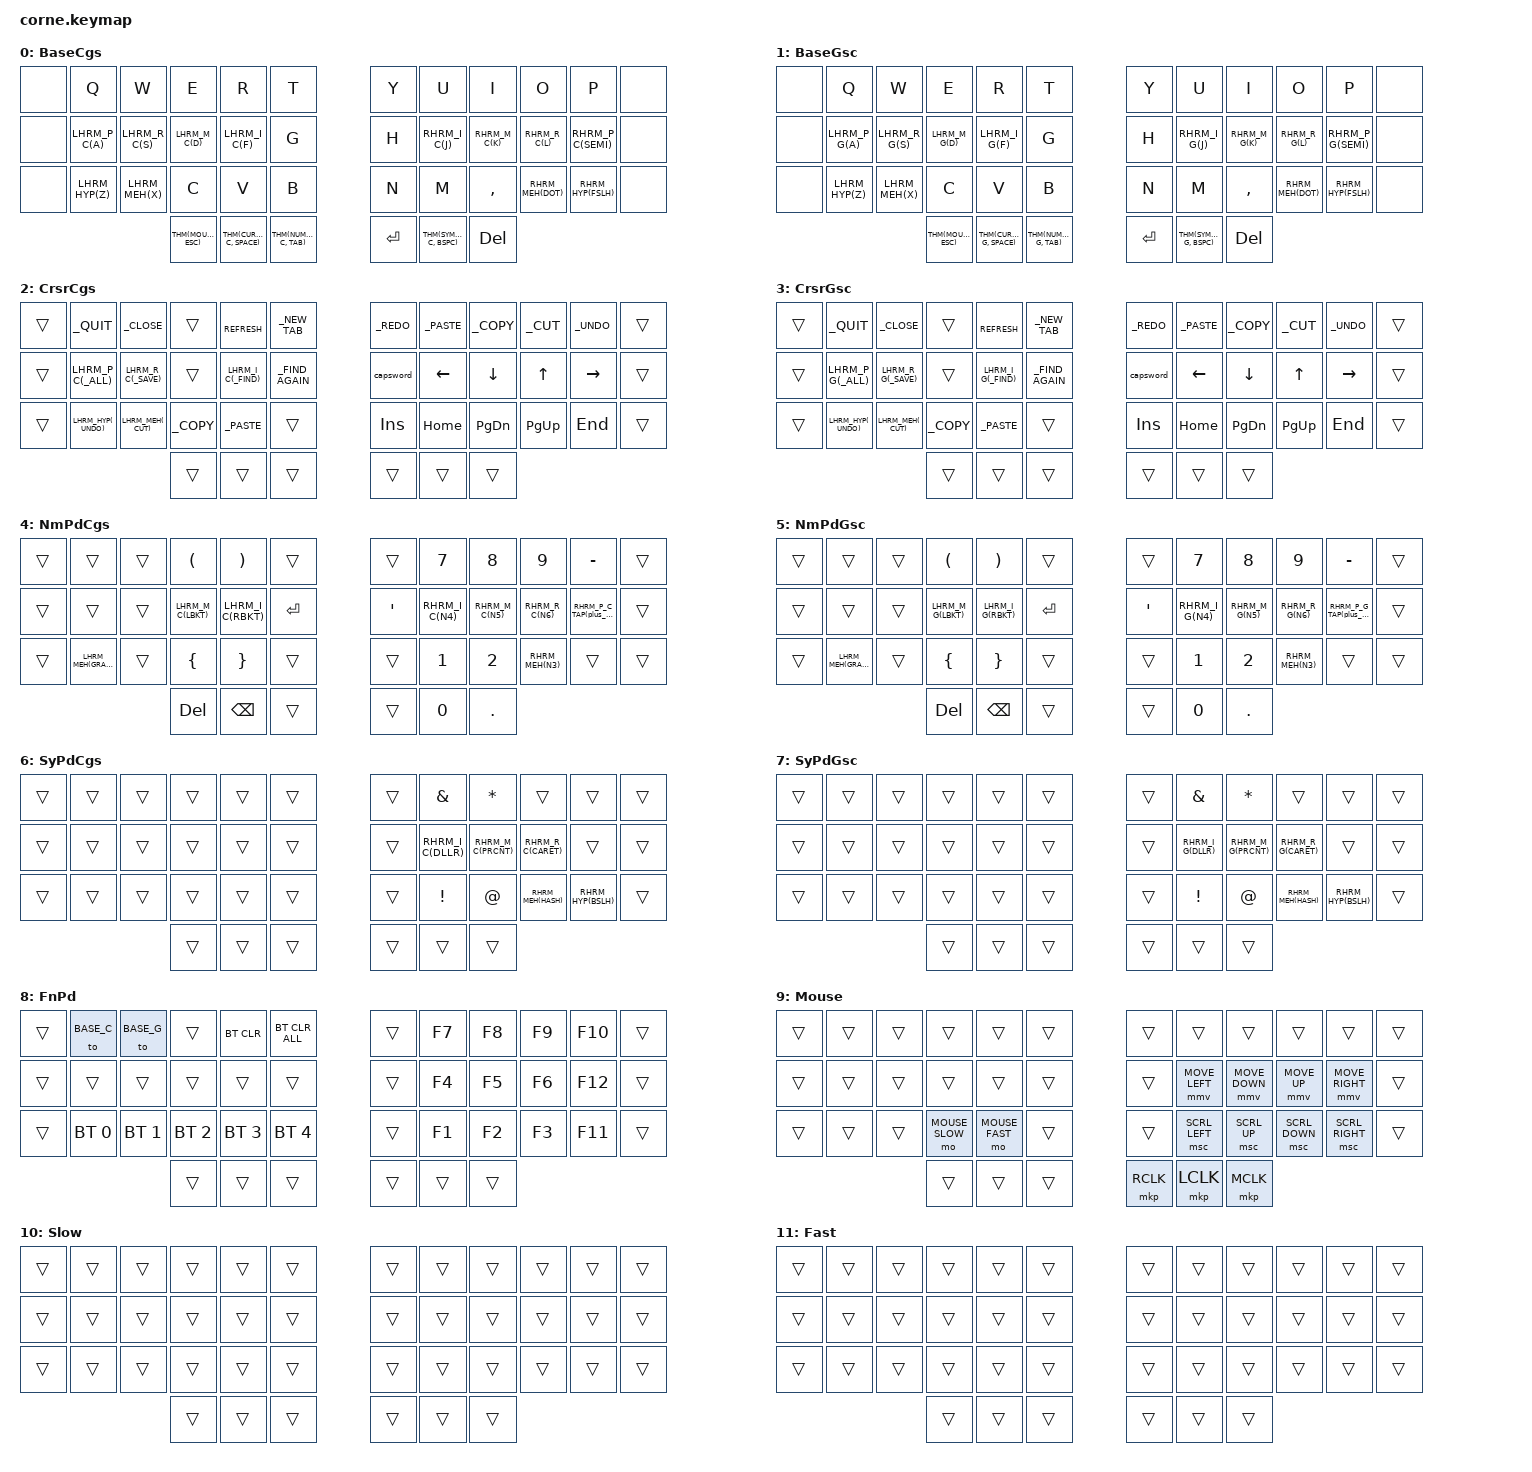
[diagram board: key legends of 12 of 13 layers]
#include <behaviors.dtsi>
#include <dt-bindings/zmk/bt.h>
#include <dt-bindings/zmk/keys.h>
#include <dt-bindings/zmk/pointing.h>
#include <input/processors.dtsi>
#include <zephyr/dt-bindings/input/input-event-codes.h>

// layer indexes
// need almost duplicate layers that override taps on the home row keys

// _C suffix stands for CAGS
#define BASE_C 0
#define CURSOR_C 2
#define NUM_PAD_C 4
#define SYM_PAD_C 6

// _G suffix stands for GASC
#define BASE_G 1
#define CURSOR_G 3
#define NUM_PAD_G 5
#define SYM_PAD_G 7

// layers that do not override taps on the home row keys
#define FCN_PAD 8
#define MOUSE 9
#define MOUSE_SLOW 10   // key 27 on MOUSE layer (hold 36 + 27)
#define MOUSE_FAST 11        // key 28 on MOUSE layer (hold 36 + 28)
#define FUNCTION 12

// #define NAV 7
// #define SYM 8
// #define EXTRA 9

/*
| Left Half:                  |  | Right Half:                 |
| 00 | 01 | 02 | 03 | 04 | 05 |  | 06 | 07 | 08 | 09 | 10 | 11 |
| 12 | 13 | 14 | 15 | 16 | 17 |  | 18 | 19 | 20 | 21 | 22 | 23 |
| 24 | 25 | 26 | 27 | 28 | 29 |  | 30 | 31 | 32 | 33 | 34 | 35 |
|              | 36 | 37 | 38 |  | 39 | 40 | 41 |              |
*/

#define RIGHT_KEY_POSITIONS 6 7 8 9 10 11 18 19 20 21 22 23 30 31 32 33 34 35 39 40 41
#define LEFT_KEY_POSITIONS 0 1 2 3 4 5 12 13 14 15 16 17 24 25 26 27 28 29 36 37 38
// Key positions for combos
#define LGUI_KEY_POSITION_C 15
#define LTHM_KEY_POSITION 37
#define A_KEY_POSITION 13
#define S_KEY_POSITION 14
#define F_KEY_POSITION 16
#define G_KEY_POSITION 17
#define Z_KEY_POSITION 25
#define X_KEY_POSITION 26
#define C_KEY_POSITION 27
#define V_KEY_POSITION 28
/* left-thumb-middle + left rolls (subset of LEFT_KEY_POSITIONS) */
#define LTHM_ROLL_KEY_POSITIONS A_KEY_POSITION S_KEY_POSITION F_KEY_POSITION G_KEY_POSITION Z_KEY_POSITION X_KEY_POSITION C_KEY_POSITION V_KEY_POSITION
#define RT_RET_KEY_POSITION 39
#define GRAVE_KEY_POSITION 13
#define GRAVE_COMBO_KEY_POSITION 25

// support left hand only operation
// these are all the same as the default combos but with the left hand cursor layer key
// add leading _ to prevent conflicts with ZMK
#define _CUT LG(X)
#define _COPY LG(C)
#define _PASTE LG(V)
#define _UNDO LG(Z)
#define _REDO LS(LG(Z))

#define _QUIT LG(Q)
#define _CLOSE LG(W)
#define _REFRESH LG(R)
// left only: copy url, new tab and paste
#define _NEW_TAB LG(T)
#define _ALL LG(A)
#define _SAVE LG(S)
#define _FIND LG(F)
#define _FIND_AGAIN LG(G)
// #define _DELETE LG(D) this is duplicate not delete

#define LHYPER LC(LA(LG(LSHFT)))
#define LMEH LC(LA(LSHFT))
#define RHYPER RC(RA(RG(RSHFT)))
#define RMEH RC(RA(RSHFT))

// CAGS home rom mods (macOS)
#define LHRM_P_C(tap) &hrm_l_p LCTRL tap
#define LHRM_R_C(tap) &hrm_l_r LALT tap
#define LHRM_M_C(tap) &hrm_l_m LGUI tap
#define LHRM_I_C(tap) &hrm_l_i LSHFT tap
#define RHRM_I_C(tap) &hrm_r_i RSHFT tap
#define RHRM_M_C(tap) &hrm_r_m RGUI tap
#define RHRM_R_C(tap) &hrm_r_r RALT tap
#define RHRM_P_C(tap) &hrm_r_p RCTRL tap
// Custom tap (mod-morph, etc.): needs hrm_r_p_<name> with bindings = <&kp>, <&name>
#define RHRM_P_C_TAP(name) &hrm_r_p_##name RCTRL 0

// GASC home row mods (Linux/Windows)
#define LHRM_P_G(tap) &hrm_l_p LGUI tap
#define LHRM_R_G(tap) &hrm_l_r LALT tap
#define LHRM_M_G(tap) &hrm_l_m LCTRL tap
#define LHRM_I_G(tap) &hrm_l_i LSHFT tap
#define RHRM_I_G(tap) &hrm_r_i RSHFT tap
#define RHRM_M_G(tap) &hrm_r_m RCTRL tap
#define RHRM_R_G(tap) &hrm_r_r RALT tap
#define RHRM_P_G(tap) &hrm_r_p RGUI tap
// Custom tap (mod-morph, etc.): needs hrm_r_p_<name> with bindings = <&kp>, <&name>
#define RHRM_P_G_TAP(name) &hrm_r_p_##name RGUI 0

// Hyper and Meh home row mods (OS-independent)
#define LHRM_HYP(tap) &hrm_l_p LHYPER tap
#define LHRM_MEH(tap) &hrm_l_r LMEH tap
#define RHRM_MEH(tap) &hrm_r_r RMEH tap
#define RHRM_HYP(tap) &hrm_r_p RHYPER tap

// Thumb row layer-tap
#define THM(layer, tap) &thumb_ht layer tap

/*
home row timings
For advanced tuning of HRM values, see: ZMK HRM Best Practice Values [SUNAKU]
[rovrevik: ZMK HRM Best Practice Values](https://docs.google.com/spreadsheets/d/1GeZ9UrOPWeVbzzsioyp9oQYQoQKxpyiTL4z8DZa1vXg)
[TaylorKey: ZMK HRM Best Practice Values](https://docs.google.com/spreadsheets/d/1ESgObQelyz4lnKlfwLYsmofLJulOMK5RdGBsopLe2o8)
started at "normal" and moving towards "faster".
*/
#define HRM_I_TAPPING_TERM_MS       282
#define HRM_I_QUICK_TAP_MS          374
#define HRM_I_REQUIRE_PRIOR_IDLE_MS 208

#define HRM_M_TAPPING_TERM_MS       299
#define HRM_M_QUICK_TAP_MS          374
#define HRM_M_REQUIRE_PRIOR_IDLE_MS 249

#define HRM_R_TAPPING_TERM_MS       324
#define HRM_R_QUICK_TAP_MS          374
#define HRM_R_REQUIRE_PRIOR_IDLE_MS 249

#define HRM_P_TAPPING_TERM_MS       357
#define HRM_P_QUICK_TAP_MS          374
#define HRM_P_REQUIRE_PRIOR_IDLE_MS 249

// thumb row layer timings
#define THUMB_TAPPING_TERM_MS       291
#define THUMB_QUICK_TAP_MS          374

/*
combo timeout
timeout default 50ms
zmk/app/dts/bindings/zmk,combos.yaml
*/
#define COMBO_TIMEOUT_MS                    125
#define LEFT_GUI_ROLL_COMBO_TIMEOUT_MS      250
#define GUI_RETURN_ROLL_COMBO_TIMEOUT_MS    250

// input wrapping
// &mmv {
//     x-input-code = <INPUT_REL_X>;
//     y-input-code = <INPUT_REL_Y>;
//     time-to-max-speed-ms = <300>;
//     acceleration-exponent = <1>;
// };

// &msc {
//     x-input-code = <INPUT_REL_HWHEEL>;
//     y-input-code = <INPUT_REL_WHEEL>;
//     time-to-max-speed-ms = <300>;
//     acceleration-exponent = <0>;
// };
// Based on @caksoylar's config, defaults in comments
&mmv {
    delay-ms = <0>;                       // 0
    time-to-max-speed-ms = <500>;         // 300
    acceleration-exponent = <1>;          // 1
};

&msc {
    delay-ms = <0>;                       // 0
    time-to-max-speed-ms = <300>;         // 300
    acceleration-exponent = <0>;          // 0
};

&mmv_input_listener {
    precision {
        layers = <MOUSE_SLOW>;
        input-processors = <&zip_xy_scaler 1 2>;
    };
    warp {
        layers = <MOUSE_FAST>;
        input-processors = <&zip_xy_scaler 3 1>;
    };
};

/ {
    zip_scroll_scaler: zip_scroll_scaler {
      compatible = "zmk,input-processor-scaler";
      #input-processor-cells = <2>;
      type = <INPUT_EV_REL>;
      codes = <INPUT_REL_WHEEL INPUT_REL_HWHEEL>;
      track-remainders;
    };
};

&msc_input_listener {
    precision {
        layers = <MOUSE_SLOW>;
        input-processors = <&zip_scroll_scaler 1 2>;
    };
    warp {
        layers = <MOUSE_FAST>;
        input-processors = <&zip_scroll_scaler 2 1>;
    };
};

/ {
    behaviors {
        /*
        unused in favor of the more advanced hold-tap behaviors below
        hm: home_row_mods {
            compatible = "zmk,behavior-hold-tap";
            label = "HOME_ROW_MODS";
            #binding-cells = <2>;
            tapping-term-ms = <200>;
            quick_tap_ms = <0>;
            flavor = "tap-preferred";
            bindings = <&kp>, <&kp>;
            quick-tap-ms = <180>;
            global-quick-tap;
        };
        */

        /*
        Home row mods inspired by TailorKey.
        These behaviors are not really home row mods in the strict sense, but they are designed to be used on the home row keys.
        They can be used on any key, but they have optimized timings for the fingers used for the home row keys.
        Using hyper and meh in addition to the four standard home row mod keys from urob.
        */
        // Home row mod for the left index finger (main/outer/f)
        hrm_l_i: home_row_left_index {
            compatible = "zmk,behavior-hold-tap";
            #binding-cells = <2>;
            tapping-term-ms = <HRM_I_TAPPING_TERM_MS>;
            bindings = <&kp>, <&kp>;
            flavor = "tap-preferred";
            quick-tap-ms = <HRM_I_QUICK_TAP_MS>;
            require-prior-idle-ms = <HRM_I_REQUIRE_PRIOR_IDLE_MS>;
            hold-trigger-key-positions = <RIGHT_KEY_POSITIONS>;
            hold-trigger-on-release;
        };

        // Home row mod for the left middle finger
        hrm_l_m: home_row_left_middle {
            compatible = "zmk,behavior-hold-tap";
            #binding-cells = <2>;
            tapping-term-ms = <HRM_M_TAPPING_TERM_MS>;
            bindings = <&kp>, <&kp>;
            flavor = "tap-preferred";
            quick-tap-ms = <HRM_M_QUICK_TAP_MS>;
            require-prior-idle-ms = <HRM_M_REQUIRE_PRIOR_IDLE_MS>;
            hold-trigger-key-positions = <RIGHT_KEY_POSITIONS>;
            hold-trigger-on-release;
        };

        // Home row mod for the left ring finger 1
        hrm_l_r: home_row_left_ring {
            compatible = "zmk,behavior-hold-tap";
            #binding-cells = <2>;
            tapping-term-ms = <HRM_R_TAPPING_TERM_MS>;
            bindings = <&kp>, <&kp>;
            flavor = "tap-preferred";
            quick-tap-ms = <HRM_R_QUICK_TAP_MS>;
            require-prior-idle-ms = <HRM_R_REQUIRE_PRIOR_IDLE_MS>;
            hold-trigger-key-positions = <RIGHT_KEY_POSITIONS>;
            hold-trigger-on-release;
        };

        // Home row mod for the left pinky (main/inner/a)
        hrm_l_p: home_row_left_pinky {
            compatible = "zmk,behavior-hold-tap";
            #binding-cells = <2>;
            tapping-term-ms = <HRM_P_TAPPING_TERM_MS>;
            bindings = <&kp>, <&kp>;
            flavor = "tap-preferred";
            quick-tap-ms = <HRM_P_QUICK_TAP_MS>;
            require-prior-idle-ms = <HRM_P_REQUIRE_PRIOR_IDLE_MS>;
            hold-trigger-key-positions = <RIGHT_KEY_POSITIONS>;
            hold-trigger-on-release;
        };

        // Home row mod for the right index finger (main/outer/j)
        hrm_r_i: home_row_right_index {
            compatible = "zmk,behavior-hold-tap";
            #binding-cells = <2>;
            tapping-term-ms = <HRM_I_TAPPING_TERM_MS>;
            bindings = <&kp>, <&kp>;
            flavor = "tap-preferred";
            quick-tap-ms = <HRM_I_QUICK_TAP_MS>;
            require-prior-idle-ms = <HRM_I_REQUIRE_PRIOR_IDLE_MS>;
            hold-trigger-key-positions = <LEFT_KEY_POSITIONS>;
            hold-trigger-on-release;
        };

        // Home row mod for the right middle finger
        hrm_r_m: home_row_right_middle {
            compatible = "zmk,behavior-hold-tap";
            #binding-cells = <2>;
            tapping-term-ms = <HRM_M_TAPPING_TERM_MS>;
            bindings = <&kp>, <&kp>;
            flavor = "tap-preferred";
            quick-tap-ms = <HRM_M_QUICK_TAP_MS>;
            require-prior-idle-ms = <HRM_M_REQUIRE_PRIOR_IDLE_MS>;
            hold-trigger-key-positions = <LEFT_KEY_POSITIONS>;
            hold-trigger-on-release;
        };

        // Home row mod for the right ring 1
        hrm_r_r: home_row_right_ring {
            compatible = "zmk,behavior-hold-tap";
            #binding-cells = <2>;
            tapping-term-ms = <HRM_R_TAPPING_TERM_MS>;
            bindings = <&kp>, <&kp>;
            flavor = "tap-preferred";
            quick-tap-ms = <HRM_R_QUICK_TAP_MS>;
            require-prior-idle-ms = <HRM_R_REQUIRE_PRIOR_IDLE_MS>;
            hold-trigger-key-positions = <LEFT_KEY_POSITIONS>;
            hold-trigger-on-release;
        };

        // Home row mod for the right pinky (main/inner/;)
        hrm_r_p: home_row_right_pinky {
            compatible = "zmk,behavior-hold-tap";
            #binding-cells = <2>;
            tapping-term-ms = <HRM_P_TAPPING_TERM_MS>;
            bindings = <&kp>, <&kp>;
            flavor = "tap-preferred";
            quick-tap-ms = <HRM_P_QUICK_TAP_MS>;
            require-prior-idle-ms = <HRM_P_REQUIRE_PRIOR_IDLE_MS>;
            hold-trigger-key-positions = <LEFT_KEY_POSITIONS>;
            hold-trigger-on-release;
        };

        // NUM_PAD_C pinky: RCTRL hold, plus_equal tap (keymap: HRM_R_P_TAP(plus_equal))
        hrm_r_p_plus_equal: home_row_right_pinky_plus_equal {
            compatible = "zmk,behavior-hold-tap";
            display-name = "HRM pinky plus/eq";
            #binding-cells = <2>;
            tapping-term-ms = <HRM_P_TAPPING_TERM_MS>;
            bindings = <&kp>, <&plus_equal>;
            flavor = "tap-preferred";
            quick-tap-ms = <HRM_P_QUICK_TAP_MS>;
            require-prior-idle-ms = <HRM_P_REQUIRE_PRIOR_IDLE_MS>;
            hold-trigger-key-positions = <LEFT_KEY_POSITIONS>;
            hold-trigger-on-release;
        };

        /*
        para: para {
            compatible = "zmk,behavior-tap-dance";
            label = "PARA";
            #binding-cells = <0>;
            bindings = <&kp LPAR>, <&kp RPAR>;
        };
        */

        /*
        caps: caps {
            compatible = "zmk,behavior-caps-word";
            label = "CAPS";
            #binding-cells = <0>;
            continue-list = <MINUS BSPC>;
        };
        */

        capsword: capsword {
            compatible = "zmk,behavior-caps-word";
            display-name = "caps word toggle";
            #binding-cells = <0>;
            continue-list = <MINUS BSPC UNDER>;
        };

        plus_equal: plus_equal {
            compatible = "zmk,behavior-mod-morph";
            display-name = "Plus/Equal";
            #binding-cells = <0>;
            bindings = <&kp PLUS>, <&kp EQUAL>;
            mods = <(MOD_LSFT|MOD_RSFT)>;
        };

        /*
        paraless: paraless {
            compatible = "zmk,behavior-mod-morph";
            label = "PARALESS";
            bindings = <&kp LPAR>, <&kp LT>;
            #binding-cells = <0>;
            mods = <(MOD_LSFT)>;
        };
        */

        /*
        paragreat: paragreat {
            compatible = "zmk,behavior-mod-morph";
            label = "PARAGREAT";
            bindings = <&kp RPAR>, <&kp GT>;
            #binding-cells = <0>;
            mods = <(MOD_LSFT)>;
        };
        */

        thumb_ht: thumb_hold_tap {
            compatible = "zmk,behavior-hold-tap";
            display-name = "thumb row hold-tap";
            bindings = <&mo>, <&kp>;
            #binding-cells = <2>;
            tapping-term-ms = <THUMB_TAPPING_TERM_MS>;
            flavor = "balanced";
            quick-tap-ms = <THUMB_QUICK_TAP_MS>;
        };

        // MOD_LSFT = 0x02
    };

    macros {
        /*
        browsertab: browsertab {
            compatible = "zmk,behavior-macro";
            #binding-cells = <0>;
            bindings =
                <&macro_press>,
                <&kp LCTRL>,
                <&macro_tap>,
                <&kp TAB>,
                <&macro_release>,
                <&kp LCTRL>;
        };
        */

        /*
        // TODO: appswitch/tab combo not behaving as intended
        appswitch: appswitch {
            compatible = "zmk,behavior-macro";
            #binding-cells = <0>;
            wait-ms = <40>;
            tap-ms = <40>;
            bindings =
                <&macro_press>,
                <&kp LGUI>,
                <&macro_pause_for_release>,
                <&macro_tap>,
                <&kp TAB>,
                <&macro_release>,
                <&kp LGUI>;
        };
        */

        /*
        // GUI + GRAVE to switch windows in the current application on macos
        windswitch: windswitch {
            compatible = "zmk,behavior-macro";
            #binding-cells = <0>;
            wait-ms = <40>;
            tap-ms = <40>;
            bindings =
                <&macro_press>,
                <&kp LGUI>,
                <&macro_tap>,
                <&kp GRAVE>,
                <&macro_release>,
                <&kp LGUI>;
        };
        */
    };

    combos {
        compatible = "zmk,combos";

        /*
        default combos that i don't use but might be useful for reference when adding new ones
        escape {
            bindings = <&kp ESC>;
            key-positions = <13 29>;
        };

        delete {
            bindings = <&kp DEL>;
            key-positions = <15 21>;
        };

        perc {
            bindings = <&kp PRCNT>;
            key-positions = <5 17>;
        };

        equal {
            bindings = <&kp EQUAL>;
            key-positions = <28 16>;
        };

        dollar {
            bindings = <&kp DLLR>;
            key-positions = <4 16>;
        };

        hash {
            bindings = <&kp HASH>;
            key-positions = <3 15>;
        };

        at {
            bindings = <&kp AT>;
            key-positions = <2 14>;
        };

        backslash {
            bindings = <&kp BSLH>;
            key-positions = <26 14>;
        };

        copy {
            bindings = <&kp K_COPY>;
            key-positions = <28 27>;
        };

        paste {
            bindings = <&kp K_PASTE>;
            key-positions = <26 27>;
        };

        star {
            bindings = <&kp STAR>;
            key-positions = <8 20>;
        };

        slash {
            bindings = <&kp FSLH>;
            key-positions = <32 20>;
        };

        plus {
            bindings = <&kp PLUS>;
            key-positions = <7 19>;
        };

        minus {
            bindings = <&kp KP_MINUS>;
            key-positions = <31 19>;
        };

        underscore {
            bindings = <&kp UNDER>;
            key-positions = <30 18>;
        };

        leftbrack {
            bindings = <&kp LBKT>;
            key-positions = <31 32>;
        };

        rightbrack {
            bindings = <&kp RBKT>;
            key-positions = <33 32>;
        };

        para-less {
            bindings = <&paraless>;
            key-positions = <20 19>;
        };

        para-great {
            bindings = <&paragreat>;
            key-positions = <20 21>;
        };
        */

        /*
        convenience combos for common shortcuts
        these could introduce bad habits
        never ever have combos that use the home row modifiers
        */
        /*
        cut {
            timeout-ms = <COMBO_TIMEOUT_MS>;
            bindings = <&kp LG(X)>;
            key-positions = <LGUI_KEY_POSITION 26>;
        };
        // required combo because c is under cmd on the home row
        copy {
            // the default timeout-ms works fine here
            bindings = <&kp LG(C)>;
            key-positions = <LGUI_KEY_POSITION 27>;
        };
        paste {
            timeout-ms = <COMBO_TIMEOUT_MS>;
            bindings = <&kp LG(V)>;
            key-positions = <LGUI_KEY_POSITION 28>;
        };
        undo {
            timeout-ms = <COMBO_TIMEOUT_MS>;
            bindings = <&kp LG(Z)>;
            key-positions = <LGUI_KEY_POSITION 24>;
        };
        quit {
            timeout-ms = <COMBO_TIMEOUT_MS>;
            bindings = <&kp LG(Q)>;
            key-positions = <LGUI_KEY_POSITION 1>;
        };
        close {
            timeout-ms = <COMBO_TIMEOUT_MS>;
            bindings = <&kp LG(W)>;
            key-positions = <LGUI_KEY_POSITION 2>;
        };
        refresh {
            timeout-ms = <COMBO_TIMEOUT_MS>;
            bindings = <&kp LG(R)>;
            key-positions = <LGUI_KEY_POSITION 4>;
        };
        save {
            timeout-ms = <COMBO_TIMEOUT_MS>;
            bindings = <&kp LG(S)>;
            key-positions = <LGUI_KEY_POSITION 14>;
        };
        find {
            timeout-ms = <COMBO_TIMEOUT_MS>;
            bindings = <&kp LG(F)>;
            key-positions = <LGUI_KEY_POSITION 16>;
        };
        find_again {
            timeout-ms = <COMBO_TIMEOUT_MS>;
            bindings = <&kp LG(G)>;
            key-positions = <LGUI_KEY_POSITION 17>;
        };
        */

        /*
        combo_toggle_gui: toggle gui can get a little confusing.
        not clear when it is enabled
        can tell be context menus not showing up
        has triggered gui + d and accidentally deleted stuff
        combo_toggle_gui {
            timeout-ms = <COMBO_TIMEOUT_MS>;
            bindings = <&kt LGUI>;
            key-positions = <LGUI_KEY_POSITION LTHM_KEY_POSITION>;
        };
        */

        /*
        left thumb middle (CURSOR/BSPC) + left roll keys on BASE layers.
        Avoids hold-trigger-key-positions on thumb_ht (breaks cross-hand layer + J).
        Bindings match CURSOR_C left-half shortcuts where applicable.
        */
        lthm_a_cags {
            timeout-ms = <GUI_RETURN_ROLL_COMBO_TIMEOUT_MS>;
            bindings = <&kp _ALL>;
            key-positions = <LTHM_KEY_POSITION A_KEY_POSITION>;
            layers = <BASE_C>;
        };
        lthm_a_gasc {
            timeout-ms = <GUI_RETURN_ROLL_COMBO_TIMEOUT_MS>;
            bindings = <&kp _ALL>;
            key-positions = <LTHM_KEY_POSITION A_KEY_POSITION>;
            layers = <BASE_G>;
        };
        lthm_s_cags {
            timeout-ms = <GUI_RETURN_ROLL_COMBO_TIMEOUT_MS>;
            bindings = <&kp _SAVE>;
            key-positions = <LTHM_KEY_POSITION S_KEY_POSITION>;
            layers = <BASE_C>;
        };
        lthm_s_gasc {
            timeout-ms = <GUI_RETURN_ROLL_COMBO_TIMEOUT_MS>;
            bindings = <&kp _SAVE>;
            key-positions = <LTHM_KEY_POSITION S_KEY_POSITION>;
            layers = <BASE_G>;
        };
        lthm_f_cags {
            timeout-ms = <GUI_RETURN_ROLL_COMBO_TIMEOUT_MS>;
            bindings = <&kp _FIND>;
            key-positions = <LTHM_KEY_POSITION F_KEY_POSITION>;
            layers = <BASE_C>;
        };
        lthm_f_gasc {
            timeout-ms = <GUI_RETURN_ROLL_COMBO_TIMEOUT_MS>;
            bindings = <&kp _FIND>;
            key-positions = <LTHM_KEY_POSITION F_KEY_POSITION>;
            layers = <BASE_G>;
        };
        lthm_g_cags {
            timeout-ms = <GUI_RETURN_ROLL_COMBO_TIMEOUT_MS>;
            bindings = <&kp _FIND_AGAIN>;
            key-positions = <LTHM_KEY_POSITION G_KEY_POSITION>;
            layers = <BASE_C>;
        };
        lthm_g_gasc {
            timeout-ms = <GUI_RETURN_ROLL_COMBO_TIMEOUT_MS>;
            bindings = <&kp _FIND_AGAIN>;
            key-positions = <LTHM_KEY_POSITION G_KEY_POSITION>;
            layers = <BASE_G>;
        };
        lthm_z_cags {
            timeout-ms = <GUI_RETURN_ROLL_COMBO_TIMEOUT_MS>;
            bindings = <&kp _UNDO>;
            key-positions = <LTHM_KEY_POSITION Z_KEY_POSITION>;
            layers = <BASE_C>;
        };
        lthm_z_gasc {
            timeout-ms = <GUI_RETURN_ROLL_COMBO_TIMEOUT_MS>;
            bindings = <&kp _UNDO>;
            key-positions = <LTHM_KEY_POSITION Z_KEY_POSITION>;
            layers = <BASE_G>;
        };
        lthm_x_cags {
            timeout-ms = <GUI_RETURN_ROLL_COMBO_TIMEOUT_MS>;
            bindings = <&kp _CUT>;
            key-positions = <LTHM_KEY_POSITION X_KEY_POSITION>;
            layers = <BASE_C>;
        };
        lthm_x_gasc {
            timeout-ms = <GUI_RETURN_ROLL_COMBO_TIMEOUT_MS>;
            bindings = <&kp _CUT>;
            key-positions = <LTHM_KEY_POSITION X_KEY_POSITION>;
            layers = <BASE_G>;
        };
        lthm_c_cags {
            timeout-ms = <GUI_RETURN_ROLL_COMBO_TIMEOUT_MS>;
            bindings = <&kp _COPY>;
            key-positions = <LTHM_KEY_POSITION C_KEY_POSITION>;
            layers = <BASE_C>;
        };
        lthm_c_gasc {
            timeout-ms = <GUI_RETURN_ROLL_COMBO_TIMEOUT_MS>;
            bindings = <&kp _COPY>;
            key-positions = <LTHM_KEY_POSITION C_KEY_POSITION>;
            layers = <BASE_G>;
        };
        lthm_v_cags {
            timeout-ms = <GUI_RETURN_ROLL_COMBO_TIMEOUT_MS>;
            bindings = <&kp _PASTE>;
            key-positions = <LTHM_KEY_POSITION V_KEY_POSITION>;
            layers = <BASE_C>;
        };
        lthm_v_gasc {
            timeout-ms = <GUI_RETURN_ROLL_COMBO_TIMEOUT_MS>;
            bindings = <&kp _PASTE>;
            key-positions = <LTHM_KEY_POSITION V_KEY_POSITION>;
            layers = <BASE_G>;
        };

        // Cmd+Enter: D (Gui HRM, pos 15) + inner right thumb Ret (pos 39)
        // combo avoids roll sending "d" then Ret when Gui releases before Ret
        gui_return_cags {
            timeout-ms = <GUI_RETURN_ROLL_COMBO_TIMEOUT_MS>;
            bindings = <&kp LG(RET)>;
            key-positions = <LGUI_KEY_POSITION_C RT_RET_KEY_POSITION>;
            layers = <BASE_C>;
        };

        // activate_terminal: grave + under grave on base layer
        activate_terminal_cags {
            // default is sufficient timeout-ms = <COMBO_TIMEOUT_MS>;
            bindings = <&kp LC(GRAVE)>;
            key-positions = <GRAVE_KEY_POSITION GRAVE_COMBO_KEY_POSITION>;
            layers = <BASE_C>;
        };

        // comment_out_line: grave + under grave on cursor layer
        comment_out_line_cags {
            // default is sufficient timeout-ms = <COMBO_TIMEOUT_MS>;
            bindings = <&kp LG(FSLH)>;
            key-positions = <GRAVE_KEY_POSITION GRAVE_COMBO_KEY_POSITION>;
            layers = <CURSOR_C>;
        };
    };

    //

    keymap {
        compatible = "zmk,keymap";

        /*
        template
        | Left Half:            |      | Right Half:           |
        |   |   |   |   |   |   |      |   |   |   |   |   |   |
        |   |   |   |   |   |   |      |   |   |   |   |   |   |
        |   |   |   |   |   |   |      |   |   |   |   |   |   |
        |           |   |   |   |      |   |   |   |           |
        */

        /*
        Base
        | Left Half:                    |      | Right Half:                  |
        |   | Q | W | E   | R     | T   |      | Y   | U    | I   | O | P |   |
        |   | A | S | D   | F     | G   |      | H   | J    | K   | L | ; |   |
        |   | Z | X | C   | V     | B   |      | N   | M    | ,   | . | / |   |
        |           | ESC | SPACE | TAB |      | RET | BSPC | DEL |           |
        */

        /*
        thumb keys considerations:
        It is absolutly to wierd to map space to anything other than the space bar on a normal keyboard.
        It is quivalently wierd to map the space to other position than the right or left middle thumb becuase
            it is most common used and should be on the primary thumb key.

        The vast majority of keymaps have:
        - left thumb middle: SPACE
        - right thumb middle: BSPC

        There is some fricton transitioning to a normal keyboard because the the sapce key is duplicated.
        macOS: fn ESC (control) SPACE (option) TAB (command) SPACE (space bar)

        The base layer thumb keys are [Miryoku](https://github.com/manna-harbour/miryoku/tree/master/docs/reference#base)
        - left thumb outer: ESC
        - left thumb middle: SPACE
        - left thumb inner: TAB
        - right thum inner: RET
        - right thumb middle: BSPC
        - right thumb outer: DEL

        Hyper and Meh considerations:
        - Hyper commonly is mapped to hold caps so it should be triggered with pinky
        - z and x are good candidates for hyper and meh because the letters are less frequently used.
        - GUI + inner thumb (TAB) for single hand application cycling
        - GUI + inner thumb (TAB) + ` (q) for single hand application window cycling

        relocated pinky stretches:
        - ESC: pinky ESC is an awkward reach for dismissing completions
            - left thumb outer
            - removed legacy: left pinky middle outer
        - ` (GRAVE):
            - left pinky upper inner (on layer)
            - removed legacy: left pinky outer upper
        - \ (BSLH):
            - right index inner upper (on layer)
            - removed legacy: right pinky outer upper
        - ' (SQT):
            - right index middle inner (on layer)
            - removed legacy: left pinky middle outer
        - HYPER:
            - left pinky inner z (hold)
            - removed legacy: left pinky middle outer (hold)
        - FUNCTION/GLOBE:
            - removed legacy: left pinky outer lower
        */

        BASE_C {
            display-name = "BaseCgs";
            bindings = <
&none &kp Q       &kp W       &kp E           &kp R                &kp T                        &kp Y   &kp U                &kp I       &kp O         &kp P          &none
&none LHRM_P_C(A) LHRM_R_C(S) LHRM_M_C(D)     LHRM_I_C(F)          &kp G                        &kp H   RHRM_I_C(J)          RHRM_M_C(K) RHRM_R_C(L)   RHRM_P_C(SEMI) &none
&none LHRM_HYP(Z) LHRM_MEH(X) &kp C           &kp V                &kp B                        &kp N   &kp M                &kp COMMA   RHRM_MEH(DOT) RHRM_HYP(FSLH) &none
                              THM(MOUSE, ESC) THM(CURSOR_C, SPACE) THM(NUM_PAD_C, TAB)          &kp RET THM(SYM_PAD_C, BSPC) &kp DEL
            >;
        };

        BASE_G {
            display-name = "BaseGsc";
            bindings = <
&none &kp Q       &kp W       &kp E           &kp R                &kp T                        &kp Y   &kp U                &kp I       &kp O         &kp P          &none
&none LHRM_P_G(A) LHRM_R_G(S) LHRM_M_G(D)     LHRM_I_G(F)          &kp G                        &kp H   RHRM_I_G(J)          RHRM_M_G(K) RHRM_R_G(L)   RHRM_P_G(SEMI) &none
&none LHRM_HYP(Z) LHRM_MEH(X) &kp C           &kp V                &kp B                        &kp N   &kp M                &kp COMMA   RHRM_MEH(DOT) RHRM_HYP(FSLH) &none
                              THM(MOUSE, ESC) THM(CURSOR_G, SPACE) THM(NUM_PAD_G, TAB)          &kp RET THM(SYM_PAD_G, BSPC) &kp DEL
            >;
        };

        /*
        Cursor: Crsr
        | Left Half:                                          |      | Right Half:                                   |
        |   | _QUIT | _CLOSE |       | _REFRESH | _NEW_TAB    |      | _REDO    | _PASTE | _COPY | _CUT  | _UNDO |   |
        |   | _ALL  | _SAVE  |       | _FIND    | _FIND_AGAIN |      | capsword | LEFT   | DOWN  | UP    | RIGHT |   |
        |   | _UNDO | _CUT   | _COPY | _PASTE   |             |      | INS      | HOME   | PG_DN | PG_UP | END   |   |
        |                    |       |          |             |      |          |        |       |                   |
        */

        // intentionally does not have homerow mods
        // follows the pattern of only configuring system shortcuts
        // thumb key + key is similar to GUI + key
        // application shortcuts are being supported with macros

        // Right hand is based on [Miryoku](https://github.com/manna-harbour/miryoku/tree/master/docs/reference#nav)
        // capsword in favor of capslock
        // TODO: consider triggering capslock with a modifier
        // considered and rejected swapping home and end to be consistent with page down/up.

        CURSOR_C {
            display-name = "CrsrCgs";
            bindings = <
&trans &kp _QUIT       &kp _CLOSE      &trans    &kp _REFRESH    &kp _NEW_TAB                &kp _REDO &kp _PASTE &kp _COPY &kp _CUT  &kp _UNDO &trans
&trans LHRM_P_C(_ALL)  LHRM_R_C(_SAVE) &trans    LHRM_I_C(_FIND) &kp _FIND_AGAIN             &capsword &kp LEFT   &kp DOWN  &kp UP    &kp RIGHT &trans
&trans LHRM_HYP(_UNDO) LHRM_MEH(_CUT)  &kp _COPY &kp _PASTE      &trans                      &kp INS   &kp HOME   &kp PG_DN &kp PG_UP &kp END   &trans
                                       &trans    &trans          &trans                      &trans    &trans     &trans
            >;
        };

        CURSOR_G {
            display-name = "CrsrGsc";
            bindings = <
&trans &kp _QUIT       &kp _CLOSE      &trans    &kp _REFRESH    &kp _NEW_TAB                &kp _REDO &kp _PASTE &kp _COPY &kp _CUT  &kp _UNDO &trans
&trans LHRM_P_G(_ALL)  LHRM_R_G(_SAVE) &trans    LHRM_I_G(_FIND) &kp _FIND_AGAIN             &capsword &kp LEFT   &kp DOWN  &kp UP    &kp RIGHT &trans
&trans LHRM_HYP(_UNDO) LHRM_MEH(_CUT)  &kp _COPY &kp _PASTE      &trans                      &kp INS   &kp HOME   &kp PG_DN &kp PG_UP &kp END   &trans
                                       &trans    &trans          &trans                      &trans    &trans     &trans
            >;
        };

        /*
        NUM_PAD: num and sym layer
        experimental layer
        settled:
        - num row: 1234567890 (shift): !@#$%^&*() (mostly normal number pad)
        - num row: -= (shift): _+ (somewhat normal number pad)
        - top row: []\ (shift): {}|
        - middle row: ' (shift): "
        - bottom row: ,./ (shift): <>?
        */

        /*
        Number Pad: NmPd
        | Left Half:                       |      | Right Half:           |
        |   |       |   | (   | )    |     |      |   | 7 | 8 | 9 | - |   |
        |   |       |   | [   | ]    | RET |      | ' | 4 | 5 | 6 | + |   |
        |   | GRAVE |   | {   | }    |     |      |   | 1 | 2 | 3 |   |   |
        |               | DEL | BSPC |     |      |   | 0 | . |           |

        Symbol Pad: SyPd
        | Left Half:                       |      | Right Half:           |
        |   |       |   |     |      |     |      |   | & | * |   |   |   |
        |   |       |   |     |      |     |      |   | $ | % | ^ |   |   |
        |   |       |   |     |      |     |      |   | ! | @ | # | \ |   |
        |               |     |      |     |      |   |   |   |           |
        */

        NUM_PAD_C {
            display-name = "NmPdCgs";
            bindings = <
&trans &trans          &trans &kp LPAR       &kp RPAR       &trans          &trans  &kp N7         &kp N8          &kp N9          &kp MINUS                &trans
&trans &trans          &trans LHRM_M_C(LBKT) LHRM_I_C(RBKT) &kp RET         &kp SQT RHRM_I_C(N4)   RHRM_M_C(N5)    RHRM_R_C(N6)    RHRM_P_C_TAP(plus_equal) &trans
&trans LHRM_MEH(GRAVE) &trans &kp LBRC       &kp RBRC       &trans          &trans  &kp N1         &kp N2          RHRM_MEH(N3)    &trans                   &trans
                              &kp DEL        &kp BSPC       &trans          &trans  &kp N0         &kp DOT
            >;
        };

        NUM_PAD_G {
            display-name = "NmPdGsc";
            bindings = <
&trans &trans          &trans &kp LPAR       &kp RPAR       &trans          &trans  &kp N7         &kp N8          &kp N9          &kp MINUS                &trans
&trans &trans          &trans LHRM_M_G(LBKT) LHRM_I_G(RBKT) &kp RET         &kp SQT RHRM_I_G(N4)   RHRM_M_G(N5)    RHRM_R_G(N6)    RHRM_P_G_TAP(plus_equal) &trans
&trans LHRM_MEH(GRAVE) &trans &kp LBRC       &kp RBRC       &trans          &trans  &kp N1         &kp N2          RHRM_MEH(N3)    &trans                   &trans
                              &kp DEL        &kp BSPC       &trans          &trans  &kp N0         &kp DOT
            >;
        };

        SYM_PAD_C {
            display-name = "SyPdCgs";
            bindings = <
&trans &trans &trans &trans &trans &trans                                   &trans  &kp AMPS       &kp STAR        &trans          &trans         &trans
&trans &trans &trans &trans &trans &trans                                   &trans  RHRM_I_C(DLLR) RHRM_M_C(PRCNT) RHRM_R_C(CARET) &trans         &trans
&trans &trans &trans &trans &trans &trans                                   &trans  &kp EXCL       &kp AT          RHRM_MEH(HASH)  RHRM_HYP(BSLH) &trans
                     &trans &trans &trans                                   &trans  &trans         &trans
            >;
        };

        SYM_PAD_G {
            display-name = "SyPdGsc";
            bindings = <
&trans &trans &trans &trans &trans &trans                                   &trans  &kp AMPS       &kp STAR        &trans          &trans         &trans
&trans &trans &trans &trans &trans &trans                                   &trans  RHRM_I_G(DLLR) RHRM_M_G(PRCNT) RHRM_R_G(CARET) &trans         &trans
&trans &trans &trans &trans &trans &trans                                   &trans  &kp EXCL       &kp AT          RHRM_MEH(HASH)  RHRM_HYP(BSLH) &trans
                     &trans &trans &trans                                   &trans  &trans         &trans
            >;
        };

        /*
        Function Pad: FnPd
        | Left Half:                        |      | Right Half:                |
        |   | CAGS | GASC |     | C   | CA  |      |   | F7 | F8 | F9 | F10 |   |
        |   |      |      |     |     |     |      |   | F4 | F5 | F6 | F12 |   |
        |   | BT0  | BT1  | BT2 | BT3 | BT4 |      |   | F1 | F2 | F3 | F11 |   |
        |                 |     |     |     |      |   |    |    |              |

        // preserve homerow mods on left hand
        // OBE: never used these
        // &bootloader  &studio_unlock
        // Left hand, second row:
        |   |      |      |     | BL  | SU  |
        */

        FCN_PAD {
            display-name = "FnPd";
            bindings = <
&trans &to BASE_C   &to BASE_G   &trans       &bt BT_CLR   &bt BT_CLR_ALL          &trans &kp F7 &kp F8 &kp F9 &kp F10 &trans
&trans &trans       &trans       &trans       &trans       &trans                  &trans &kp F4 &kp F5 &kp F6 &kp F12 &trans
&trans &bt BT_SEL 0 &bt BT_SEL 1 &bt BT_SEL 2 &bt BT_SEL 3 &bt BT_SEL 4            &trans &kp F1 &kp F2 &kp F3 &kp F11 &trans
                                 &trans       &trans       &trans                  &trans &trans &trans
            >;
        };

        // TODO: add legend
        // TODO: invert scroll macOS versus Linux
        // Right hand is based on [Miryoku](https://github.com/manna-harbour/miryoku/tree/master/docs/reference#mouse)
        // [ZMK mouse emulation](https://zmk.dev/docs/keymaps/behaviors/mouse-emulation)
        // [](https://github.com/urob/zmk-config/blob/main/config/mouse.dtsi)
        // Key 36 (thumb): THM(MOUSE, ESC) on base layers — hold activates MOUSE.
        // Keys 27/28 (C/V): &mo speed modifiers on this layer only; no letter output.
        // Precision: hold 36 + 27. Warp: hold 36 + 28. Default speed: hold 36 only.
        MOUSE {
            display-name = "Mouse";
            bindings = <
&trans &trans &trans &trans         &trans         &trans           &trans    &trans         &trans         &trans         &trans          &trans
&trans &trans &trans &trans         &trans         &trans           &trans    &mmv MOVE_LEFT &mmv MOVE_DOWN &mmv MOVE_UP   &mmv MOVE_RIGHT &trans
&trans &trans &trans &mo MOUSE_SLOW &mo MOUSE_FAST &trans           &trans    &msc SCRL_LEFT &msc SCRL_UP   &msc SCRL_DOWN &msc SCRL_RIGHT &trans
                     &trans         &trans         &trans           &mkp RCLK &mkp LCLK      &mkp MCLK
            >;
        };

        MOUSE_SLOW {
            display-name = "Slow";
            bindings = <
&trans &trans &trans &trans &trans &trans           &trans &trans &trans &trans &trans &trans
&trans &trans &trans &trans &trans &trans           &trans &trans &trans &trans &trans &trans
&trans &trans &trans &trans &trans &trans           &trans &trans &trans &trans &trans &trans
                     &trans &trans &trans           &trans &trans &trans
            >;
        };

        MOUSE_FAST {
            display-name = "Fast";
            bindings = <
&trans &trans &trans &trans &trans &trans           &trans &trans &trans &trans &trans &trans
&trans &trans &trans &trans &trans &trans           &trans &trans &trans &trans &trans &trans
&trans &trans &trans &trans &trans &trans           &trans &trans &trans &trans &trans &trans
                     &trans &trans &trans           &trans &trans &trans
            >;
        };

        /*
        function layer to emulate the lower outer left globe/fn key on macOS keyboards
        */
        FUNCTION {
            display-name = "Function";
            bindings = <
&trans             &trans &trans &trans &trans &trans          &trans &trans &trans &trans &trans &trans
&trans             &trans &trans &trans &trans &trans          &trans &trans &trans &trans &trans &trans
&lt FUNCTION GLOBE &trans &trans &trans &trans &trans          &trans &trans &trans &trans &trans &trans
                                 &trans &trans &trans          &trans &trans &trans
            >;
        };

        /*
        -------------------------------------------------------------------------------
        |  TAB |  1  |  2  |  3  |  4  |  5  |   |  6  |  7  |  8  |  9  |  0  | BKSP |
        | BTCLR| BT1 | BT2 | BT3 | BT4 | BT5 |   | LFT | DWN |  UP | RGT |     |      |
        | SHFT |     |     |     |     |     |   |     |     |     |     |     |      |
        | GUI | CTRL | SHFT | LWR | SPC |   | ENT | RSE  | BKSP | ALT | ESC |
        */
        /*
        NAV {
            display-name = "Nav";

            bindings = <
&trans     &kp N1 &kp N2   &kp N3   &kp N4      &kp N5             &kp N6  &kp N7 &kp N8 &kp N9 &kp N0 &trans
&caps_word &trans &trans   &kp UP   &browsertab &kp PG_UP          &kp N0  &kp N4 &kp N5 &kp N6 &trans &trans
&trans     &trans &kp LEFT &kp DOWN &kp RIGHT   &kp PG_DN          &trans  &kp N1 &kp N2 &kp N3 &trans &trans
                           &kp LGUI &trans      &kp SPACE          &kp RET &trans &trans
            >;
        };
        */

        /*
        | Left Half:            |      | Right Half:           |
        |   | ! | @ | # | $ | % |      | ^ | & | * | ( | ) |   |
        |   |   |   |   |   |   |      |   | - | = | [ | ] |   |
        |   |   |   |   |   |   |      |   |   |   |   | \ |   |
        |           |   |   |   |      |   |   |   |           |
        */
        /*
        SYM {
            display-name = "Symbols";
            bindings = <
&trans &kp EXCL &kp AT &kp HASH &kp DLLR &kp PRCNT          &kp CARET &kp AMPS  &kp STAR  &kp LPAR &kp RPAR &trans
&trans &trans   &trans &trans   &trans   &trans             &trans    &kp MINUS &kp EQUAL &kp LBKT &kp RBKT &trans
&trans &trans   &trans &trans   &trans   &trans             &trans    &trans    &trans    &trans   &kp BSLH &trans
                       &trans   &trans   &trans             &trans    &trans    &trans
            >;
        };
        */

        /*
        EXTRA {
            display-name = "Extra";
            bindings = <
&trans &trans &trans         &mmv MOVE_UP   &trans          &msc SCRL_UP            &trans &trans &trans &trans &trans &trans
&trans &trans &mmv MOVE_LEFT &mmv MOVE_DOWN &mmv MOVE_RIGHT &msc SCRL_DOWN          &trans &trans &trans &trans &trans &trans
&trans &trans &trans         &trans         &trans          &trans                  &trans &trans &trans &trans &trans &trans
                             &trans         &trans          &trans                  &trans &trans &trans
            >;
        };
        */
    };

    conditional_layers {
        compatible = "zmk,conditional-layers";

        fcn_cags {
            if-layers = <CURSOR_C SYM_PAD_C>;
            then-layer = <FCN_PAD>;
        };

        fcn_gasc {
            if-layers = <CURSOR_G SYM_PAD_G>;
            then-layer = <FCN_PAD>;
        };
    };
};
